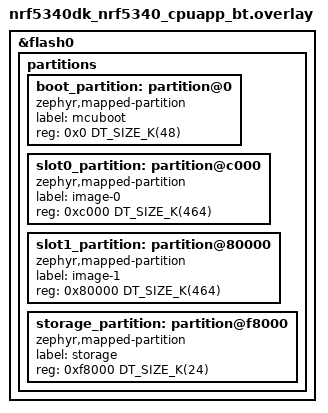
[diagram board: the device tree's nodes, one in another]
/*
 * Copyright (c) 2026 Nordic Semiconductor ASA
 *
 * SPDX-License-Identifier: LicenseRef-Nordic-5-Clause
 */

/delete-node/ &boot_partition;
/delete-node/ &slot0_partition;
/delete-node/ &slot1_partition;
/delete-node/ &storage_partition;

&flash0 {
	partitions {
		boot_partition: partition@0 {
			compatible = "zephyr,mapped-partition";
			label = "mcuboot";
			reg = <0x0 DT_SIZE_K(48)>;
		};

		slot0_partition: partition@c000 {
			compatible = "zephyr,mapped-partition";
			label = "image-0";
			reg = <0xc000 DT_SIZE_K(464)>;
		};

		slot1_partition: partition@80000 {
			compatible = "zephyr,mapped-partition";
			label = "image-1";
			reg = <0x80000 DT_SIZE_K(464)>;
		};

		storage_partition: partition@f8000 {
			compatible = "zephyr,mapped-partition";
			label = "storage";
			reg = <0xf8000 DT_SIZE_K(24)>;
		};
	};
};
